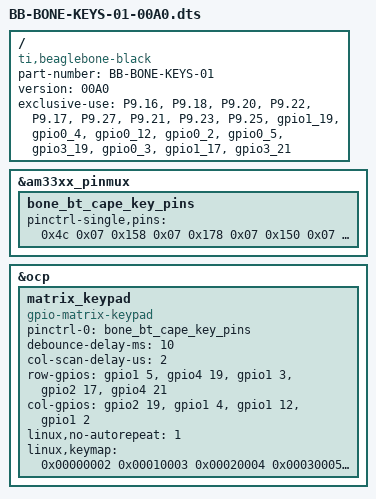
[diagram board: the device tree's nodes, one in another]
/*
 * Copyright (C) 2013 CircuitCo
 *
 * This program is free software; you can redistribute it and/or modify
 * it under the terms of the GNU General Public License version 2 as
 * published by the Free Software Foundation.
 */
/dts-v1/;
/plugin/;

/ {
	compatible = "ti,beaglebone-black";

	/* identification */
	part-number = "BB-BONE-KEYS-01";
	version = "00A0";

	/* state the resources this cape uses */
	exclusive-use =
		/* the pin header uses */
		"P9.16", 
		"P9.18", 
		"P9.20", 
		"P9.22", 
		"P9.17", 
		"P9.27", 
		"P9.21", 
		"P9.23", 
		"P9.25", 
			
		/* the hardware IP uses */
		"gpio1_19",     /* col-0 */     
		"gpio0_4",	    /* col-1 */  
		"gpio0_12",	    /* col-2 */  
		"gpio0_2",	    /* col-3 */
		"gpio0_5",      /* row-0 */
		"gpio3_19",     /* row-1 */  
		"gpio0_3",	    /* row-2 */ 
		"gpio1_17",     /* row-3 */ 
		"gpio3_21";     /* row-4 */ 

	fragment@0 {
		target = <&am33xx_pinmux>;
		__overlay__ {
			bone_bt_cape_key_pins: bone_bt_cape_key_pins {
				pinctrl-single,pins = <							
					0x4c 0x07 /* gpmc_a3.gpio1_19 			OUTPUT_PULLDOWN | MODE7  */
					0x158 0x07 /* spi0_d1.gpio0_4 			OUTPUT_PULLDOWN | MODE7  */
					0x178 0x07 /* uart1_ctsn.gpio0_12 		OUTPUT_PULLDOWN | MODE7  */
					0x150 0x07 /* spi0_sclk.gpio0_2 		OUTPUT_PULLDOWN | MODE7  */					
					0x15c 0x37 /* spi0_cs0.gpio0_5   		INPUT_PULLUP | MODE7  */					
					0x1a4 0x37 /* mcasp0_fsr.gpio3_19 		INPUT_PULLUP | MODE 7  */
					0x154 0x37 /* spi0_d0.gpio0_3 			INPUT_PULLUP | MODE 7  */
					0x44 0x37 /* gpmc_a1.gpio1_17   		INPUT_PULLUP | MODE 7  */
					0x1ac 0x37 /* mcasp0_ahclkx.gpio3_21   	INPUT_PULLUP | MODE 7  */

				>;
			};
		};
	};
	             
	fragment@1 {
		target = <&ocp>;
		__overlay__ {
			matrix_keypad {
				compatible = "gpio-matrix-keypad";
				pinctrl-names = "default";
				pinctrl-0 = <&bone_bt_cape_key_pins>;
				debounce-delay-ms = <10>;
				col-scan-delay-us = <2>;
						
				row-gpios = <&gpio1 5 0	
						 &gpio4 19 0	
						 &gpio1 3 0
						 &gpio2 17 0
						 &gpio4 21 0>;
				
				col-gpios = <&gpio2 19 0
						&gpio1 4 0
						&gpio1 12 0
						&gpio1 2 0>;
				 
				/* gpio-activelow = <1>; */
				linux,no-autorepeat = <1>;

				linux,keymap = <0x00000002
								0x00010003
								0x00020004
								0x00030005
								0x01000006
								0x01010007
								0x01020008
								0x01030009
								0x0200000a
								0x0201000b
								0x0202000c
								0x0203000d
								0x0300000f
								0x03010010
								0x03020011
								0x03030012
								0x04000013
								0x04010014
								0x04020015
								0x04030016>;
			};
		};
	};
};

